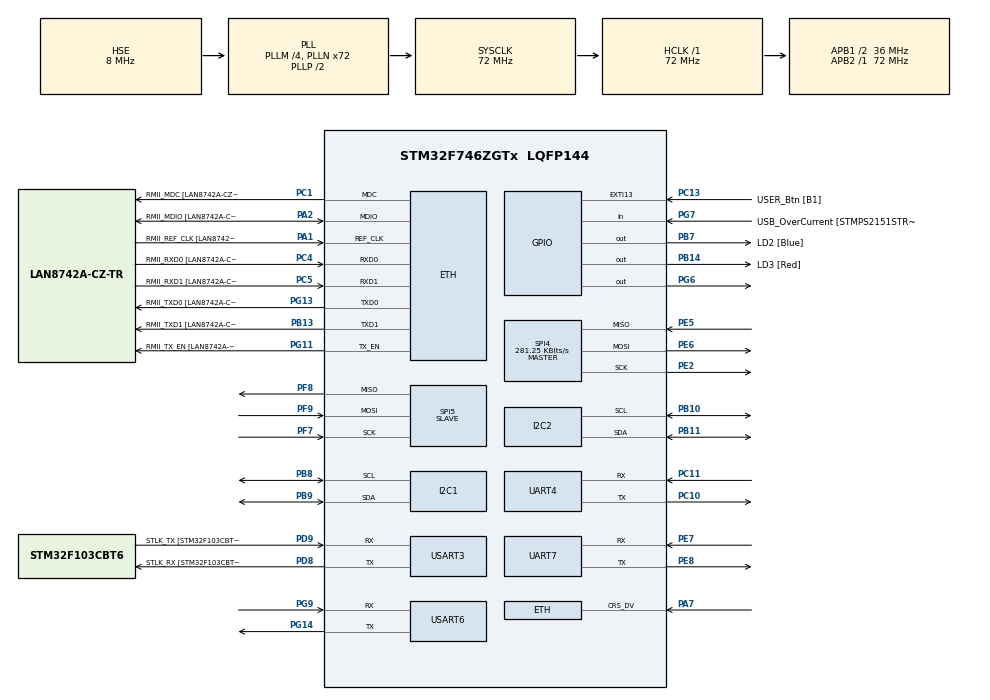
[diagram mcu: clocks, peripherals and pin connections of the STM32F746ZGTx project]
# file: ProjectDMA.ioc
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CORTEX_M7.CPU_DCache=Disabled
CORTEX_M7.CPU_ICache=Disabled
CORTEX_M7.MPU_Control=__NULL
Dma.I2C1_RX.0.Direction=DMA_PERIPH_TO_MEMORY
Dma.I2C1_RX.0.FIFOMode=DMA_FIFOMODE_DISABLE
Dma.I2C1_RX.0.Instance=DMA1_Stream0
Dma.I2C1_RX.0.MemDataAlignment=DMA_MDATAALIGN_BYTE
Dma.I2C1_RX.0.MemInc=DMA_MINC_ENABLE
Dma.I2C1_RX.0.Mode=DMA_NORMAL
Dma.I2C1_RX.0.PeriphDataAlignment=DMA_PDATAALIGN_BYTE
Dma.I2C1_RX.0.PeriphInc=DMA_PINC_DISABLE
Dma.I2C1_RX.0.Priority=DMA_PRIORITY_LOW
Dma.I2C1_TX.1.Direction=DMA_MEMORY_TO_PERIPH
Dma.I2C1_TX.1.FIFOMode=DMA_FIFOMODE_DISABLE
Dma.I2C1_TX.1.Instance=DMA1_Stream6
Dma.I2C1_TX.1.MemDataAlignment=DMA_MDATAALIGN_BYTE
Dma.I2C1_TX.1.MemInc=DMA_MINC_ENABLE
Dma.I2C1_TX.1.Mode=DMA_NORMAL
Dma.I2C1_TX.1.PeriphDataAlignment=DMA_PDATAALIGN_BYTE
Dma.I2C1_TX.1.PeriphInc=DMA_PINC_DISABLE
Dma.I2C1_TX.1.Priority=DMA_PRIORITY_LOW
Dma.I2C2_RX.2.Direction=DMA_PERIPH_TO_MEMORY
Dma.I2C2_RX.2.FIFOMode=DMA_FIFOMODE_DISABLE
Dma.I2C2_RX.2.Instance=DMA1_Stream3
Dma.I2C2_RX.2.MemDataAlignment=DMA_MDATAALIGN_BYTE
Dma.I2C2_RX.2.MemInc=DMA_MINC_ENABLE
Dma.I2C2_RX.2.Mode=DMA_NORMAL
Dma.I2C2_RX.2.PeriphDataAlignment=DMA_PDATAALIGN_BYTE
Dma.I2C2_RX.2.PeriphInc=DMA_PINC_DISABLE
Dma.I2C2_RX.2.Priority=DMA_PRIORITY_LOW
Dma.I2C2_TX.3.Direction=DMA_MEMORY_TO_PERIPH
Dma.I2C2_TX.3.FIFOMode=DMA_FIFOMODE_DISABLE
Dma.I2C2_TX.3.Instance=DMA1_Stream7
Dma.I2C2_TX.3.MemDataAlignment=DMA_MDATAALIGN_BYTE
Dma.I2C2_TX.3.MemInc=DMA_MINC_ENABLE
Dma.I2C2_TX.3.Mode=DMA_NORMAL
Dma.I2C2_TX.3.PeriphDataAlignment=DMA_PDATAALIGN_BYTE
Dma.I2C2_TX.3.PeriphInc=DMA_PINC_DISABLE
Dma.I2C2_TX.3.Priority=DMA_PRIORITY_LOW
Dma.Request0=I2C1_RX
Dma.Request1=I2C1_TX
Dma.Request10=USART6_RX
Dma.Request11=USART6_TX
Dma.Request2=I2C2_RX
Dma.Request3=I2C2_TX
Dma.Request4=SPI4_RX
Dma.Request5=SPI4_TX
Dma.Request6=SPI5_RX
Dma.Request7=SPI5_TX
Dma.Request8=UART4_RX
Dma.Request9=UART4_TX
Dma.SPI4_RX.4.Direction=DMA_PERIPH_TO_MEMORY
Dma.SPI4_RX.4.FIFOMode=DMA_FIFOMODE_DISABLE
Dma.SPI4_RX.4.Instance=DMA2_Stream0
Dma.SPI4_RX.4.MemDataAlignment=DMA_MDATAALIGN_BYTE
Dma.SPI4_RX.4.MemInc=DMA_MINC_ENABLE
Dma.SPI4_RX.4.Mode=DMA_NORMAL
Dma.SPI4_RX.4.PeriphDataAlignment=DMA_PDATAALIGN_BYTE
Dma.SPI4_RX.4.PeriphInc=DMA_PINC_DISABLE
Dma.SPI4_RX.4.Priority=DMA_PRIORITY_LOW
Dma.SPI4_TX.5.Direction=DMA_MEMORY_TO_PERIPH
Dma.SPI4_TX.5.FIFOMode=DMA_FIFOMODE_DISABLE
Dma.SPI4_TX.5.Instance=DMA2_Stream1
Dma.SPI4_TX.5.MemDataAlignment=DMA_MDATAALIGN_BYTE
Dma.SPI4_TX.5.MemInc=DMA_MINC_ENABLE
Dma.SPI4_TX.5.Mode=DMA_NORMAL
Dma.SPI4_TX.5.PeriphDataAlignment=DMA_PDATAALIGN_BYTE
Dma.SPI4_TX.5.PeriphInc=DMA_PINC_DISABLE
Dma.SPI4_TX.5.Priority=DMA_PRIORITY_LOW
Dma.SPI5_RX.6.Direction=DMA_PERIPH_TO_MEMORY
Dma.SPI5_RX.6.FIFOMode=DMA_FIFOMODE_DISABLE
Dma.SPI5_RX.6.Instance=DMA2_Stream3
Dma.SPI5_RX.6.MemDataAlignment=DMA_MDATAALIGN_BYTE
Dma.SPI5_RX.6.MemInc=DMA_MINC_ENABLE
Dma.SPI5_RX.6.Mode=DMA_NORMAL
Dma.SPI5_RX.6.PeriphDataAlignment=DMA_PDATAALIGN_BYTE
Dma.SPI5_RX.6.PeriphInc=DMA_PINC_DISABLE
Dma.SPI5_RX.6.Priority=DMA_PRIORITY_LOW
Dma.SPI5_TX.7.Direction=DMA_MEMORY_TO_PERIPH
Dma.SPI5_TX.7.FIFOMode=DMA_FIFOMODE_DISABLE
Dma.SPI5_TX.7.Instance=DMA2_Stream4
Dma.SPI5_TX.7.MemDataAlignment=DMA_MDATAALIGN_BYTE
Dma.SPI5_TX.7.MemInc=DMA_MINC_ENABLE
Dma.SPI5_TX.7.Mode=DMA_NORMAL
Dma.SPI5_TX.7.PeriphDataAlignment=DMA_PDATAALIGN_BYTE
Dma.SPI5_TX.7.PeriphInc=DMA_PINC_DISABLE
Dma.SPI5_TX.7.Priority=DMA_PRIORITY_LOW
Dma.UART4_RX.8.Direction=DMA_PERIPH_TO_MEMORY
Dma.UART4_RX.8.FIFOMode=DMA_FIFOMODE_DISABLE
Dma.UART4_RX.8.Instance=DMA1_Stream2
Dma.UART4_RX.8.MemDataAlignment=DMA_MDATAALIGN_BYTE
Dma.UART4_RX.8.MemInc=DMA_MINC_ENABLE
Dma.UART4_RX.8.Mode=DMA_NORMAL
Dma.UART4_RX.8.PeriphDataAlignment=DMA_PDATAALIGN_BYTE
Dma.UART4_RX.8.PeriphInc=DMA_PINC_DISABLE
Dma.UART4_RX.8.Priority=DMA_PRIORITY_LOW
Dma.UART4_TX.9.Direction=DMA_MEMORY_TO_PERIPH
Dma.UART4_TX.9.FIFOMode=DMA_FIFOMODE_DISABLE
Dma.UART4_TX.9.Instance=DMA1_Stream4
Dma.UART4_TX.9.MemDataAlignment=DMA_MDATAALIGN_BYTE
Dma.UART4_TX.9.MemInc=DMA_MINC_ENABLE
Dma.UART4_TX.9.Mode=DMA_NORMAL
Dma.UART4_TX.9.PeriphDataAlignment=DMA_PDATAALIGN_BYTE
Dma.UART4_TX.9.PeriphInc=DMA_PINC_DISABLE
Dma.UART4_TX.9.Priority=DMA_PRIORITY_LOW
Dma.USART6_RX.10.Direction=DMA_PERIPH_TO_MEMORY
Dma.USART6_RX.10.FIFOMode=DMA_FIFOMODE_DISABLE
Dma.USART6_RX.10.Instance=DMA2_Stream2
Dma.USART6_RX.10.MemDataAlignment=DMA_MDATAALIGN_BYTE
Dma.USART6_RX.10.MemInc=DMA_MINC_ENABLE
Dma.USART6_RX.10.Mode=DMA_NORMAL
Dma.USART6_RX.10.PeriphDataAlignment=DMA_PDATAALIGN_BYTE
Dma.USART6_RX.10.PeriphInc=DMA_PINC_DISABLE
Dma.USART6_RX.10.Priority=DMA_PRIORITY_LOW
Dma.USART6_TX.11.Direction=DMA_MEMORY_TO_PERIPH
Dma.USART6_TX.11.FIFOMode=DMA_FIFOMODE_DISABLE
Dma.USART6_TX.11.Instance=DMA2_Stream6
Dma.USART6_TX.11.MemDataAlignment=DMA_MDATAALIGN_BYTE
Dma.USART6_TX.11.MemInc=DMA_MINC_ENABLE
Dma.USART6_TX.11.Mode=DMA_NORMAL
Dma.USART6_TX.11.PeriphDataAlignment=DMA_PDATAALIGN_BYTE
Dma.USART6_TX.11.PeriphInc=DMA_PINC_DISABLE
Dma.USART6_TX.11.Priority=DMA_PRIORITY_LOW
ETH.MediaInterface=HAL_ETH_RMII_MODE
I2C1.OwnAddress=10
I2C1.Timing=0x00808CD2
I2C2.OwnAddress=11
I2C2.Timing=0x00808CD2
LWIP.BSP.number=1
LWIP.GATEWAY_ADDRESS=000.000.000.000
LWIP.IP_ADDRESS=193.168.001.120
LWIP.LWIP_DHCP=0
LWIP.NETMASK_ADDRESS=255.255.255.000
LWIP.Version=v2.1.2_Cube
LWIP0.BSP.STBoard=false
LWIP0.BSP.api=BSP_COMPONENT_DRIVER
LWIP0.BSP.component=LAN8742
LWIP0.BSP.instance=LAN8742
LWIP0.BSP.name=Driver_PHY
LWIP0.BSP.semaphore=S_LAN8742
LWIP0.BSP.solution=LAN8742
Mcu.Family=STM32F7
Mcu.Name=STM32F746ZGTx
Mcu.Package=LQFP144
NVIC.DMA1_Stream0_IRQn=true\:0\:0\:false\:false\:true\:false\:true\:true
NVIC.DMA1_Stream2_IRQn=true\:0\:0\:false\:false\:true\:false\:true\:true
NVIC.DMA1_Stream3_IRQn=true\:0\:0\:false\:false\:true\:false\:true\:true
NVIC.DMA1_Stream4_IRQn=true\:0\:0\:false\:false\:true\:false\:true\:true
NVIC.DMA1_Stream6_IRQn=true\:0\:0\:false\:false\:true\:false\:true\:true
NVIC.DMA1_Stream7_IRQn=true\:0\:0\:false\:false\:true\:false\:true\:true
NVIC.DMA2_Stream0_IRQn=true\:0\:0\:false\:false\:true\:false\:true\:true
NVIC.DMA2_Stream1_IRQn=true\:0\:0\:false\:false\:true\:false\:true\:true
NVIC.DMA2_Stream2_IRQn=true\:0\:0\:false\:false\:true\:false\:true\:true
NVIC.DMA2_Stream3_IRQn=true\:0\:0\:false\:false\:true\:false\:true\:true
NVIC.DMA2_Stream4_IRQn=true\:0\:0\:false\:false\:true\:false\:true\:true
NVIC.DMA2_Stream6_IRQn=true\:0\:0\:false\:false\:true\:false\:true\:true
NVIC.I2C1_ER_IRQn=true\:0\:0\:false\:false\:true\:true\:true\:true
NVIC.I2C1_EV_IRQn=true\:0\:0\:false\:false\:true\:true\:true\:true
NVIC.I2C2_ER_IRQn=true\:0\:0\:false\:false\:true\:true\:true\:true
NVIC.I2C2_EV_IRQn=true\:0\:0\:false\:false\:true\:true\:true\:true
NVIC.PriorityGroup=NVIC_PRIORITYGROUP_4
NVIC.SPI4_IRQn=true\:0\:0\:true\:false\:true\:true\:true\:true
NVIC.SPI5_IRQn=true\:0\:0\:false\:false\:true\:true\:true\:true
NVIC.UART4_IRQn=true\:0\:0\:false\:false\:true\:true\:true\:true
NVIC.UART7_IRQn=true\:0\:0\:false\:false\:true\:true\:true\:true
NVIC.USART6_IRQn=true\:0\:0\:false\:false\:true\:true\:true\:true
PA1.GPIO_Label=RMII_REF_CLK [LAN8742A-CZ-TR_REFCLK0]
PA1.Mode=RMII
PA1.Signal=ETH_REF_CLK
PA13.GPIO_Label=TMS
PA13.Mode=Serial_Wire
PA13.Signal=SYS_JTMS-SWDIO
PA14.GPIO_Label=TCK
PA14.Mode=Serial_Wire
PA14.Signal=SYS_JTCK-SWCLK
PA2.GPIO_Label=RMII_MDIO [LAN8742A-CZ-TR_MDIO]
PA2.Mode=RMII
PA2.Signal=ETH_MDIO
PA7.Mode=RMII
PA7.Signal=ETH_CRS_DV
PB10.GPIO_Pu=GPIO_PULLUP
PB10.Mode=I2C
PB10.Signal=I2C2_SCL
PB11.GPIO_Pu=GPIO_PULLUP
PB11.Mode=I2C
PB11.Signal=I2C2_SDA
PB13.GPIO_Label=RMII_TXD1 [LAN8742A-CZ-TR_TXD1]
PB13.Mode=RMII
PB13.Signal=ETH_TXD1
PB14.GPIO_Label=LD3 [Red]
PB14.Signal=GPIO_Output
PB7.GPIO_Label=LD2 [Blue]
PB7.Signal=GPIO_Output
PB8.GPIO_Pu=GPIO_PULLUP
PB8.Mode=I2C
PB8.Signal=I2C1_SCL
PB9.GPIO_Pu=GPIO_PULLUP
PB9.Mode=I2C
PB9.Signal=I2C1_SDA
PC1.GPIO_Label=RMII_MDC [LAN8742A-CZ-TR_MDC]
PC1.Mode=RMII
PC1.Signal=ETH_MDC
PC10.Mode=Asynchronous
PC10.Signal=UART4_TX
PC11.Mode=Asynchronous
PC11.Signal=UART4_RX
PC13.GPIO_Label=USER_Btn [B1]
PC13.Signal=GPXTI13
PC14/OSC32_IN.Mode=LSE-External-Oscillator
PC14/OSC32_IN.Signal=RCC_OSC32_IN
PC15/OSC32_OUT.Mode=LSE-External-Oscillator
PC15/OSC32_OUT.Signal=RCC_OSC32_OUT
PC4.GPIO_Label=RMII_RXD0 [LAN8742A-CZ-TR_RXD0]
PC4.Mode=RMII
PC4.Signal=ETH_RXD0
PC5.GPIO_Label=RMII_RXD1 [LAN8742A-CZ-TR_RXD1]
PC5.Mode=RMII
PC5.Signal=ETH_RXD1
PD8.GPIO_Label=STLK_RX [STM32F103CBT6_PA3]
PD8.GPIO_PuPd=GPIO_PULLUP
PD8.Mode=Asynchronous
PD8.Signal=USART3_TX
PD9.GPIO_Label=STLK_TX [STM32F103CBT6_PA2]
PD9.GPIO_PuPd=GPIO_PULLUP
PD9.Mode=Asynchronous
PD9.Signal=USART3_RX
PE2.GPIO_PuPd=GPIO_NOPULL
PE2.Mode=Full_Duplex_Master
PE2.Signal=SPI4_SCK
PE5.Mode=Full_Duplex_Master
PE5.Signal=SPI4_MISO
PE6.Mode=Full_Duplex_Master
PE6.Signal=SPI4_MOSI
PE7.Mode=Asynchronous
PE7.Signal=UART7_RX
PE8.Mode=Asynchronous
PE8.Signal=UART7_TX
PF7.GPIO_PuPd=GPIO_NOPULL
PF7.Mode=Full_Duplex_Slave
PF7.Signal=SPI5_SCK
PF8.Mode=Full_Duplex_Slave
PF8.Signal=SPI5_MISO
PF9.Mode=Full_Duplex_Slave
PF9.Signal=SPI5_MOSI
PG11.GPIO_Label=RMII_TX_EN [LAN8742A-CZ-TR_TXEN]
PG11.Mode=RMII
PG11.Signal=ETH_TX_EN
PG13.GPIO_Label=RMII_TXD0 [LAN8742A-CZ-TR_TXD0]
PG13.Mode=RMII
PG13.Signal=ETH_TXD0
PG14.Mode=Asynchronous
PG14.Signal=USART6_TX
PG6.Signal=GPIO_Output
PG7.GPIO_Label=USB_OverCurrent [STMPS2151STR_FAULT]
PG7.Signal=GPIO_Input
PG9.Mode=Asynchronous
PG9.Signal=USART6_RX
PH0/OSC_IN.GPIO_Label=MCO [STM32F103CBT6_PA8]
PH0/OSC_IN.Mode=HSE-External-Clock-Source
PH0/OSC_IN.Signal=RCC_OSC_IN
PH1/OSC_OUT.Mode=HSE-External-Clock-Source
PH1/OSC_OUT.Signal=RCC_OSC_OUT
ProjectManager.HeapSize=0x200
ProjectManager.StackSize=0x400
ProjectManager.TargetToolchain=STM32CubeIDE
RCC.48MHZClocksFreq_Value=24000000
RCC.AHBFreq_Value=72000000
RCC.APB1CLKDivider=RCC_HCLK_DIV2
RCC.APB1Freq_Value=36000000
RCC.APB1TimFreq_Value=72000000
RCC.APB2Freq_Value=72000000
RCC.APB2TimFreq_Value=72000000
RCC.CortexFreq_Value=72000000
RCC.HCLKFreq_Value=72000000
RCC.HSE_VALUE=8000000
RCC.HSI_VALUE=16000000
RCC.PLLM=4
RCC.PLLMUL=RCC_PLL_MUL9
RCC.PLLN=72
RCC.PLLQ=3
RCC.PLLSourceVirtual=RCC_PLLSOURCE_HSE
RCC.PRESCALERUSB=RCC_USBCLKSOURCE_PLL_DIV1_5
RCC.SYSCLKFreq_VALUE=72000000
RCC.SYSCLKSource=RCC_SYSCLKSOURCE_PLLCLK
RCC.SYSCLKSourceVirtual=RCC_SYSCLKSOURCE_PLLCLK
RCC.USBFreq_Value=48000000
RCC.VCOOutputFreq_Value=144000000
SPI4.BaudRatePrescaler=SPI_BAUDRATEPRESCALER_256
SPI4.CalculateBaudRate=281.25 KBits/s
SPI4.DataSize=SPI_DATASIZE_8BIT
SPI4.Direction=SPI_DIRECTION_2LINES
SPI4.Mode=SPI_MODE_MASTER
SPI4.VirtualType=VM_MASTER
SPI5.DataSize=SPI_DATASIZE_8BIT
SPI5.Direction=SPI_DIRECTION_2LINES
SPI5.Mode=SPI_MODE_SLAVE
SPI5.VirtualType=VM_SLAVE
USART3.VirtualMode-Asynchronous=VM_ASYNC
USART6.VirtualMode-Asynchronous=VM_ASYNC
VP_LWIP_VS_Enabled.Mode=Enabled
board=NUCLEO-F746ZG

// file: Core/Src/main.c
/* USER CODE BEGIN Header */
/**
  ******************************************************************************
  * @file           : main.c
  * @brief          : Main program body
  ******************************************************************************
  * @attention
  *
  * Copyright (c) 2025 STMicroelectronics.
  * All rights reserved.
  *
  * This software is licensed under terms that can be found in the LICENSE file
  * in the root directory of this software component.
  * If no LICENSE file comes with this software, it is provided AS-IS.
  *
  ******************************************************************************
  */
/* USER CODE END Header */
#include "main.h"
#include "dma.h"
#include "i2c.h"
#include "lwip.h"
#include "spi.h"
#include "usart.h"
#include "gpio.h"

/* USER CODE BEGIN Includes */
#include "rtg_main.h"
/* USER CODE END Includes */

void SystemClock_Config(void);

int main(void)
{

  /* MCU Configuration--------------------------------------------------------*/

  /* Reset of all peripherals, Initializes the Flash interface and the Systick. */
  HAL_Init();

  /* Configure the system clock */
  SystemClock_Config();

  /* Initialize all configured peripherals */
  MX_GPIO_Init();
  MX_DMA_Init();
  MX_I2C2_Init();
  MX_UART7_Init();
  MX_LWIP_Init();
  MX_SPI5_Init();
  MX_USART3_UART_Init();
  MX_I2C1_Init();
  MX_SPI4_Init();
  MX_UART4_Init();
  MX_USART6_UART_Init();

  /* Infinite loop */
  /* USER CODE BEGIN WHILE */
  rtg_main();
  while (1)
  {
    /* USER CODE END WHILE */

  }
}

void SystemClock_Config(void)
{
  RCC_OscInitTypeDef RCC_OscInitStruct = {0};
  RCC_ClkInitTypeDef RCC_ClkInitStruct = {0};

  /** Configure LSE Drive Capability
  */
  HAL_PWR_EnableBkUpAccess();

  /** Configure the main internal regulator output voltage
  */
  __HAL_RCC_PWR_CLK_ENABLE();
  __HAL_PWR_VOLTAGESCALING_CONFIG(PWR_REGULATOR_VOLTAGE_SCALE3);

  /** Initializes the RCC Oscillators according to the specified parameters
  * in the RCC_OscInitTypeDef structure.
  */
  RCC_OscInitStruct.OscillatorType = RCC_OSCILLATORTYPE_HSE;
  RCC_OscInitStruct.HSEState = RCC_HSE_BYPASS;
  RCC_OscInitStruct.PLL.PLLState = RCC_PLL_ON;
  RCC_OscInitStruct.PLL.PLLSource = RCC_PLLSOURCE_HSE;
  RCC_OscInitStruct.PLL.PLLM = 4;
  RCC_OscInitStruct.PLL.PLLN = 72;
  RCC_OscInitStruct.PLL.PLLP = RCC_PLLP_DIV2;
  RCC_OscInitStruct.PLL.PLLQ = 3;
  if (HAL_RCC_OscConfig(&RCC_OscInitStruct) != HAL_OK)
  {
    Error_Handler();
  }

  /** Initializes the CPU, AHB and APB buses clocks
  */
  RCC_ClkInitStruct.ClockType = RCC_CLOCKTYPE_HCLK|RCC_CLOCKTYPE_SYSCLK
                              |RCC_CLOCKTYPE_PCLK1|RCC_CLOCKTYPE_PCLK2;
  RCC_ClkInitStruct.SYSCLKSource = RCC_SYSCLKSOURCE_PLLCLK;
  RCC_ClkInitStruct.AHBCLKDivider = RCC_SYSCLK_DIV1;
  RCC_ClkInitStruct.APB1CLKDivider = RCC_HCLK_DIV2;
  RCC_ClkInitStruct.APB2CLKDivider = RCC_HCLK_DIV1;

  if (HAL_RCC_ClockConfig(&RCC_ClkInitStruct, FLASH_LATENCY_2) != HAL_OK)
  {
    Error_Handler();
  }
}

void Error_Handler(void)
{
  __disable_irq();
  while (1)
  {
  }
}
